# DPHY_TX0 register map
Vendor: Texas Instruments
Peripheral module from a debugger description file (folder J7_AHP).
Registers are 32-bit, read-write, reset 0x0 unless marked. A register's access mark holds for its fields unless they carry their own. Offsets are as the file gives them; lines under a group give offsets from that group; [hi:lo] are bit positions; {n}, {i} and the like mark numbered series; 'fields as' and 'values as' point back to an identical list; <NAME> marks a mode.

## DPHY_TX0 (part 1 of 2)
{0x0+4i} WIZ16B8M4CDT_CMN0_CMN_ANA_TBIT{i} (i=0..2)
  [31:0] CMN0_ANA_TBIT{i} — Analog Test register {i}
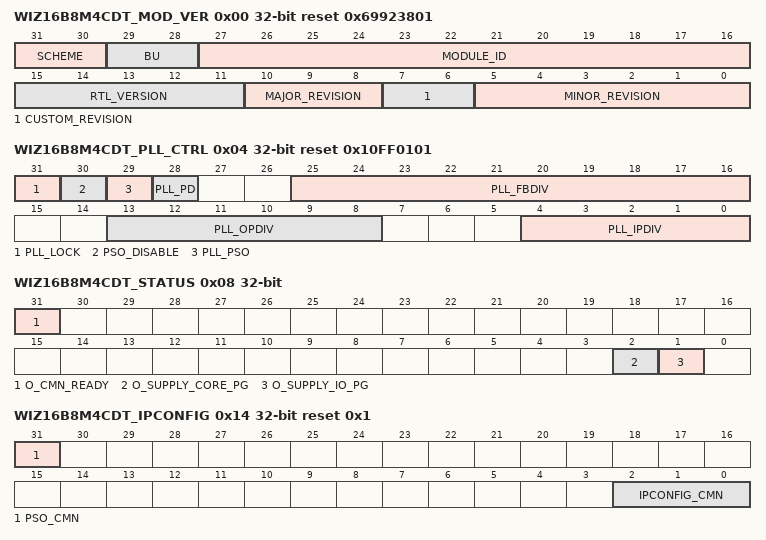
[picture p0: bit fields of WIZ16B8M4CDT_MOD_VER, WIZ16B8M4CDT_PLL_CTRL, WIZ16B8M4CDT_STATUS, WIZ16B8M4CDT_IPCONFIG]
0x00 WIZ16B8M4CDT_MOD_VER ro reset 0x69923801
  [31:30] SCHEME — Module Scheme
  [29:28] BU — Module Business Unit
  [27:16] MODULE_ID — WIZ16B8M4CDT module ID.
  [15:11] RTL_VERSION
  [10:8] MAJOR_REVISION
  [7:6] CUSTOM_REVISION
  [5:0] MINOR_REVISION
0x04 WIZ16B8M4CDT_PLL_CTRL access per field reset 0x10FF0101
  [31] PLL_LOCK ro — Signal to indicate that PLL has got locked. 1: PLL locked to required frequency 0: PLL not yet locked
  [30] PSO_DISABLE rw — Disables the ability to switch off the analog switched power islands in the lane when in the ultra-low power state
  [29] PLL_PSO rw — Power Shut Off signal for PLL 1: PLL shutoff 0: PLL power ON
  [28] PLL_PD rw — Power down signal for PLL (Does not switch off the PLL supply) 1: PLL is powered down 0: PLL is active
  [25:16] PLL_FBDIV rw — DPHY TX PLL VCO Feedback Divider ratio. Feedback divider value = ROUND ((Data Rate * 2 * pll_opdiv * pll_ipdiv) / PLL reference clock frequency)
  [13:8] PLL_OPDIV rw — DPHY TX PLL OUTCLK Divider ratio.<BR> 6'h01: Div by 1, 2.5 Gbps - 1.25 Gbps<BR> 6'h02: Div by 2, 1.24 Gbps - 630 Mbps<BR> 6'h04: Div by 4, 620 Mbps - 320 Mbps<BR> 6'h08: Div by 8, 310 Mbps - 160 Mbps<BR> 6'h10: Div by 16, 150 Mbps - 80 Mbps
  [4:0] PLL_IPDIV rw — DPHY TX PLL REFCLK Input Divider ratio.<BR> 5'h01: Div by 1, 9.6 MHz - <19.2 MHz<BR> 5'h02: Div by 2, 19.2 MHz - <38.4 MHz<BR> 5'h04: Div by 4, 38.4 MHz - < 76.8 MHz<BR> 5'h08: Div by 8, 76.8 MHz - < 150 MHz
0x08 WIZ16B8M4CDT_STATUS ro
  [31] O_CMN_READY — System Should check this during Power up Initialisation
  [2] O_SUPPLY_CORE_PG — The indicates the core supply is good.
  [1] O_SUPPLY_IO_PG — The indicates the IO supply is good.
0x0C WIZ16B8M4CDT_CMN0_CMN_ANA_TBIT3 access not given reset not defined
0x0C WIZ16B8M4CDT_RST_CTRL
  [31] LANE_RSTB_CMN — DPHY System Reset for Common Module - required to be released after APB register programming; See DPHY PMA specification for details of DPHY power up sequence
0x10 WIZ16B8M4CDT_CMN0_CMN_ANA_TBIT4
  [31:0] CMN0_ANA_TBIT4 — Analog Test register 4
0x10 WIZ16B8M4CDT_PSM_FREQ reset 0x1
  [7:0] PSM_CLOCK_FREQ — Static value based on System PSM clock frequency. The signal must be driven with a value such that the internal psm frequency of the divided psm clock is 1 MHz
0x14 WIZ16B8M4CDT_CMN0_CMN_ANA_TBIT5
  [7:0] CMN0_ANA_TBIT5 — Analog Test register 5
0x14 WIZ16B8M4CDT_IPCONFIG reset 0x1
  [31] PSO_CMN — Power Shutoff signal for CMN 1: CMN is power OFF 0: CMN is power ON
  [2:0] IPCONFIG_CMN — This signal decides which clock lane acts as master clock lane to all data lanes. Needed only for RXIP. Bit[2]: Reserved CASE {Bit[1],Bit[0]}: 00: Left RX clk lane provides clock to all left and right data lanes. 01: Left RX clk lane provides clock to all right data lanes, Right RX clk lane provides clock to all left data lanes. 10: Right RX clk lane provides clock to all right data lanes, Left RX clk lane provides clock to all left data lanes. 11: Right RX clk lane provides clock to all left and right data lanes.
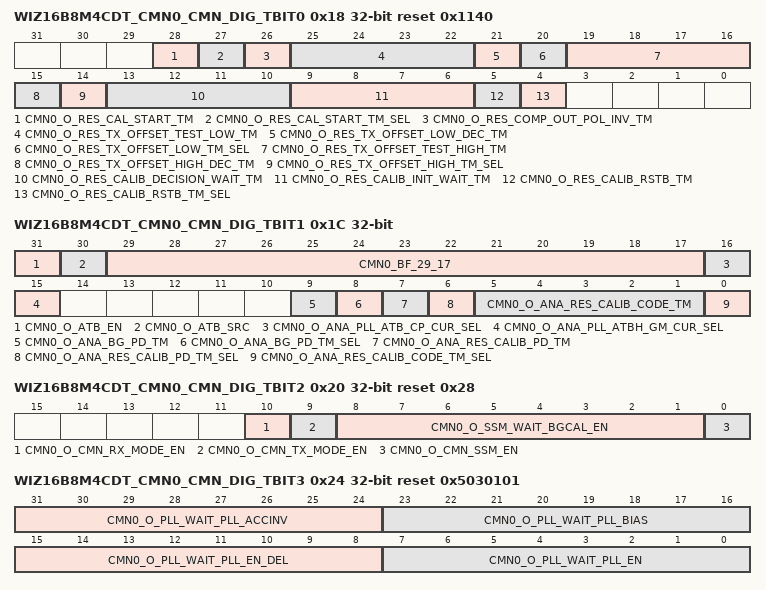
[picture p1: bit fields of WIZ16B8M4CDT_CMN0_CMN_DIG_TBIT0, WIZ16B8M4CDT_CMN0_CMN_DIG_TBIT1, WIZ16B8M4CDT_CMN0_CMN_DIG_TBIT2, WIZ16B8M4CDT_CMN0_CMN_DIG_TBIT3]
0x18 WIZ16B8M4CDT_CMN0_CMN_DIG_TBIT0 reset 0x1140
  [28] CMN0_O_RES_CAL_START_TM — res_cal_start in test mode
  [27] CMN0_O_RES_CAL_START_TM_SEL — res_cal_start select from test_mode
  [26] CMN0_O_RES_COMP_OUT_POL_INV_TM — Invert polarity for resistor calib comparator output
  [25:22] CMN0_O_RES_TX_OFFSET_TEST_LOW_TM — o_res_tx_offset_test_low_TM - Res calib manipulation code for res calib code low
  [21] CMN0_O_RES_TX_OFFSET_LOW_DEC_TM — o_res_tx_offset_low_dec_TM asserted - Perform increment manipulation on res calib code if o_res_tx_offset_low_TM_sel is asserted
  [20] CMN0_O_RES_TX_OFFSET_LOW_TM_SEL — o_res_tx_offset_low_TM_sel asserted - Enable offset manipulation for res calib code low
  [19:16] CMN0_O_RES_TX_OFFSET_TEST_HIGH_TM — o_res_tx_offset_test_high_TM - Res calib manipulation code for res calib code high
  [15] CMN0_O_RES_TX_OFFSET_HIGH_DEC_TM — o_res_tx_offset_high_dec_TM asserted - Perform increment manipulation on res calib code if o_res_tx_offset_high_TM_sel is asserted
  [14] CMN0_O_RES_TX_OFFSET_HIGH_TM_SEL — o_res_tx_offset_high_TM_sel asserted - Enable offset manipulation for res calib code high
  [13:10] CMN0_O_RES_CALIB_DECISION_WAIT_TM — res_calib decision wait time
  [9:6] CMN0_O_RES_CALIB_INIT_WAIT_TM — res_calib initial wait time
  [5] CMN0_O_RES_CALIB_RSTB_TM — w_res_calib_rstb value in testmode
  [4] CMN0_O_RES_CALIB_RSTB_TM_SEL — w_res_calib_rstb select from test_mode
0x1C WIZ16B8M4CDT_CMN0_CMN_DIG_TBIT1
  [31] CMN0_O_ATB_EN — ATB probing enabled
  [30] CMN0_O_ATB_SRC — Select IO for atb probing
  [29:17] CMN0_BF_29_17 — atb sel
  [16] CMN0_O_ANA_PLL_ATB_CP_CUR_SEL — o_ana_pll_atb_cp_cur_sel
  [15] CMN0_O_ANA_PLL_ATBH_GM_CUR_SEL — o_ana_pll_atbh_gm_cur_sel
  [9] CMN0_O_ANA_BG_PD_TM — o_ana_bg_pd value in testmode
  [8] CMN0_O_ANA_BG_PD_TM_SEL — o_ana_bg_pd select from test_mode
  [7] CMN0_O_ANA_RES_CALIB_PD_TM — o_ana_res_calib_pd value in testmode
  [6] CMN0_O_ANA_RES_CALIB_PD_TM_SEL — o_ana_res_calib_pd select from test_mode
  [5:1] CMN0_O_ANA_RES_CALIB_CODE_TM — o_ana_res_calib_code value in test_mode
  [0] CMN0_O_ANA_RES_CALIB_CODE_TM_SEL — o_ana_res_calib_code select from test_mode
0x20 WIZ16B8M4CDT_CMN0_CMN_DIG_TBIT2 reset 0x28
  [10] CMN0_O_CMN_RX_MODE_EN — Enable CMN RX related StateMachines
  [9] CMN0_O_CMN_TX_MODE_EN — Enable CMN TX related StateMachines
  [8:1] CMN0_O_SSM_WAIT_BGCAL_EN — Wait time for Calibrations enable after bandgap is enabled (in us)
  [0] CMN0_O_CMN_SSM_EN — Enable CMN startup state machine
0x24 WIZ16B8M4CDT_CMN0_CMN_DIG_TBIT3 reset 0x5030101
  [31:24] CMN0_O_PLL_WAIT_PLL_ACCINV — Wait time in pll_accinv (in us)
  [23:16] CMN0_O_PLL_WAIT_PLL_BIAS — Wait time in pll_bias (in us)
  [15:8] CMN0_O_PLL_WAIT_PLL_EN_DEL — Wait time in pll_en_del (in us)
  [7:0] CMN0_O_PLL_WAIT_PLL_EN — Wait time in PLL en (in us)
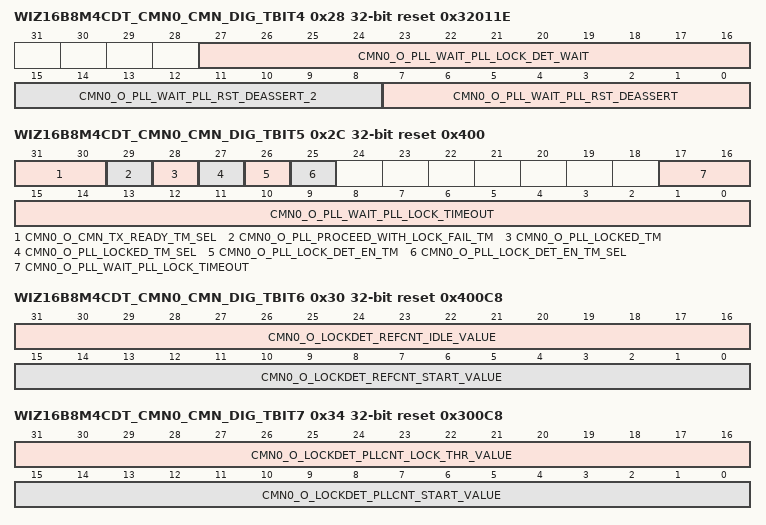
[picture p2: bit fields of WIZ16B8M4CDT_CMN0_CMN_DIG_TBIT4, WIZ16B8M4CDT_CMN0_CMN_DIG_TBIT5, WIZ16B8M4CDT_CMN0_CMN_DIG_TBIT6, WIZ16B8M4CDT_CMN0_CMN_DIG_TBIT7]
0x28 WIZ16B8M4CDT_CMN0_CMN_DIG_TBIT4 reset 0x32011E
  [27:16] CMN0_O_PLL_WAIT_PLL_LOCK_DET_WAIT — Wait time in pll_lock_det_wait (in us)
  [15:8] CMN0_O_PLL_WAIT_PLL_RST_DEASSERT_2 — Wait time in pll_rst_deassert_2ndset (in us)
  [7:0] CMN0_O_PLL_WAIT_PLL_RST_DEASSERT — Wait time in pll_rst_deassert (in us)
0x2C WIZ16B8M4CDT_CMN0_CMN_DIG_TBIT5 reset 0x400
  [31:30] CMN0_O_CMN_TX_READY_TM_SEL — ATB probing enabled
  [29] CMN0_O_PLL_PROCEED_WITH_LOCK_FAIL_TM — o_ana_pll_atb_cp_cur_sel
  [28] CMN0_O_PLL_LOCKED_TM — Forced value of pll_locked going to fsm = 1
  [27] CMN0_O_PLL_LOCKED_TM_SEL — pll_locked going to fsm forced from test registers
  [26] CMN0_O_PLL_LOCK_DET_EN_TM — Forced value of pll_lock_det_en = 1
  [25] CMN0_O_PLL_LOCK_DET_EN_TM_SEL — pll_lock_det_en forced from test registers
  [17:0] CMN0_O_PLL_WAIT_PLL_LOCK_TIMEOUT — Wait time for pll_lock_timeout (in us)
0x30 WIZ16B8M4CDT_CMN0_CMN_DIG_TBIT6 reset 0x400C8
  [31:16] CMN0_O_LOCKDET_REFCNT_IDLE_VALUE — refcnt idle value for PLL lock detect module
  [15:0] CMN0_O_LOCKDET_REFCNT_START_VALUE — refcnt start value for PLL lock detect module
0x34 WIZ16B8M4CDT_CMN0_CMN_DIG_TBIT7 reset 0x300C8
  [31:16] CMN0_O_LOCKDET_PLLCNT_LOCK_THR_VALUE — pllcnt lock threshold value for PLL lock detect module
  [15:0] CMN0_O_LOCKDET_PLLCNT_START_VALUE — pllcnt start value for PLL lock detect module
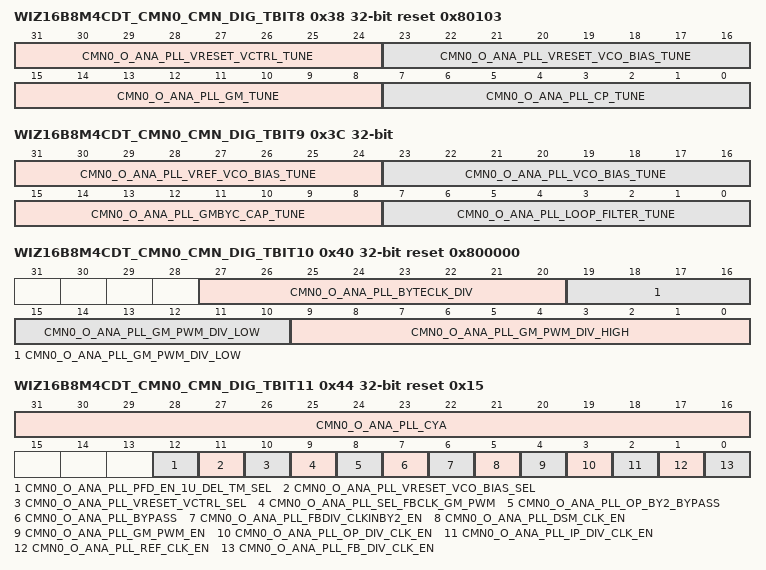
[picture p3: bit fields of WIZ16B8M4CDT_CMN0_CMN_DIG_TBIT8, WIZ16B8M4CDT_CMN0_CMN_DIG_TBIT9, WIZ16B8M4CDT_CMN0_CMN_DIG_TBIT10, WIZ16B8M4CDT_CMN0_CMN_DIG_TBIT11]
0x38 WIZ16B8M4CDT_CMN0_CMN_DIG_TBIT8 reset 0x80103
  [31:24] CMN0_O_ANA_PLL_VRESET_VCTRL_TUNE — unconnected, intended for vreset_vctrl(CP output) progrmmability
  [23:16] CMN0_O_ANA_PLL_VRESET_VCO_BIAS_TUNE — Programmability for vco bias(gmbyc) initial voltage
  [15:8] CMN0_O_ANA_PLL_GM_TUNE — gm tune value for PLL
  [7:0] CMN0_O_ANA_PLL_CP_TUNE — Charge Pump Tune value for PLL
0x3C WIZ16B8M4CDT_CMN0_CMN_DIG_TBIT9
  [31:24] CMN0_O_ANA_PLL_VREF_VCO_BIAS_TUNE — Tuning Control for reference vco bias in PLL
  [23:16] CMN0_O_ANA_PLL_VCO_BIAS_TUNE — Tuning Control for PLL vco bias
  [15:8] CMN0_O_ANA_PLL_GMBYC_CAP_TUNE — gmbyc tune value for PLL
  [7:0] CMN0_O_ANA_PLL_LOOP_FILTER_TUNE — Tuning Control for loop filter
0x40 WIZ16B8M4CDT_CMN0_CMN_DIG_TBIT10 reset 0x800000
  [27:20] CMN0_O_ANA_PLL_BYTECLK_DIV — Byteclk divider value
  [19:10] CMN0_O_ANA_PLL_GM_PWM_DIV_LOW — Low division value setting for the gm PWM control divider
  [9:0] CMN0_O_ANA_PLL_GM_PWM_DIV_HIGH — High division value setting for the gm PWM control divider
0x44 WIZ16B8M4CDT_CMN0_CMN_DIG_TBIT11 reset 0x15
  [31:16] CMN0_O_ANA_PLL_CYA — Drives pllda_cya going to ANA
  [12] CMN0_O_ANA_PLL_PFD_EN_1U_DEL_TM_SEL — Testmode signal for selecting 1us delayed for pll_pfd_reset_n
  [11] CMN0_O_ANA_PLL_VRESET_VCO_BIAS_SEL — vreset_vctrl_gmbyc is set inside the pll_vreset_gen
  [10] CMN0_O_ANA_PLL_VRESET_VCTRL_SEL — vreset_vctrl is set to ground inside the pll_vreset_gen
  [9] CMN0_O_ANA_PLL_SEL_FBCLK_GM_PWM — Enable mode to use feedback clock as the PWM control input for the gm stage
  [8] CMN0_O_ANA_PLL_OP_BY2_BYPASS — Mode to bypass the divide by 2 in the PLL output which generates clk_bit and clk_bitb
  [7] CMN0_O_ANA_PLL_BYPASS — Bypass PLL and pass refclk as output
  [6] CMN0_O_ANA_PLL_FBDIV_CLKINBY2_EN — Enable division by 2 on the feedback divider input clock
  [5] CMN0_O_ANA_PLL_DSM_CLK_EN — Enable for dsm clock output to digital
  [4] CMN0_O_ANA_PLL_GM_PWM_EN — Enable PWM control of the gm, else it will operate in the continuous mode
  [3] CMN0_O_ANA_PLL_OP_DIV_CLK_EN — Enable for op divider clock output to digital
  [2] CMN0_O_ANA_PLL_IP_DIV_CLK_EN — Enable for ip divider output to digital
  [1] CMN0_O_ANA_PLL_REF_CLK_EN — enables refclk to PLL
  [0] CMN0_O_ANA_PLL_FB_DIV_CLK_EN — Enable for feedback clock output to digital
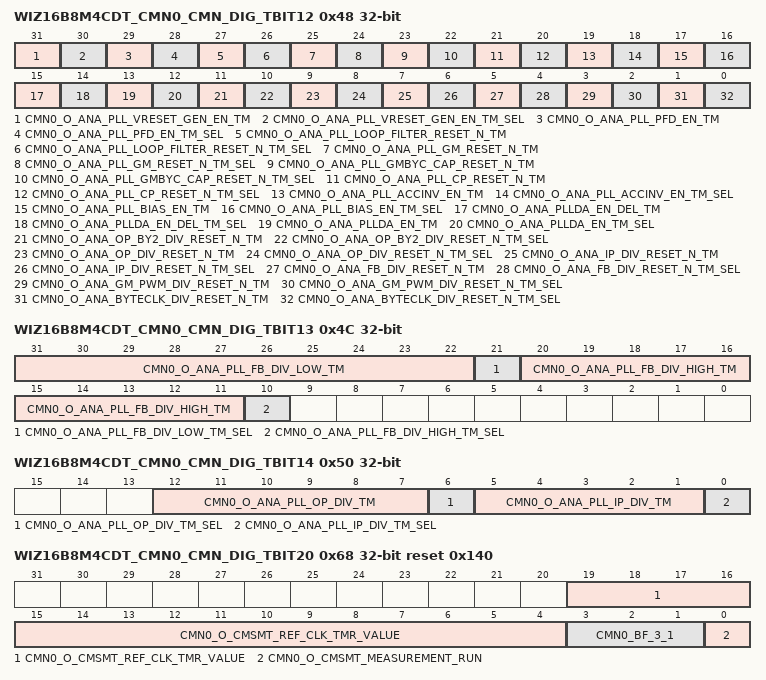
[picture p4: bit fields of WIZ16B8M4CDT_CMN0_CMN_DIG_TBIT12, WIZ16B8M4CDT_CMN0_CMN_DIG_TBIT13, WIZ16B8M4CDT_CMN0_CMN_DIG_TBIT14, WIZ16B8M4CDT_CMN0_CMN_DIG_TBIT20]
0x48 WIZ16B8M4CDT_CMN0_CMN_DIG_TBIT12
  [31] CMN0_O_ANA_PLL_VRESET_GEN_EN_TM — Forced value of pll_vreset_gen_en = 1
  [30] CMN0_O_ANA_PLL_VRESET_GEN_EN_TM_SEL — pll_vreset_gen_en forced from test registers
  [29] CMN0_O_ANA_PLL_PFD_EN_TM — Forced value of pllda_pfd_en = 1
  [28] CMN0_O_ANA_PLL_PFD_EN_TM_SEL — pllda_pfd_en forced from test registers
  [27] CMN0_O_ANA_PLL_LOOP_FILTER_RESET_N_TM — Forced value of pll_loop_filter_reset_n = 1
  [26] CMN0_O_ANA_PLL_LOOP_FILTER_RESET_N_TM_SEL — pll_loop_filter_reset_n is drivne from test registers
  [25] CMN0_O_ANA_PLL_GM_RESET_N_TM — Forced value of pll_gm_reset_n = 1
  [24] CMN0_O_ANA_PLL_GM_RESET_N_TM_SEL — pll_gm_reset_n is drivne from test registers
  [23] CMN0_O_ANA_PLL_GMBYC_CAP_RESET_N_TM — Forced value of pll_gmbyc_cap_reset_n = 1
  [22] CMN0_O_ANA_PLL_GMBYC_CAP_RESET_N_TM_SEL — pll_gmbyc_cap_reset_n is drivne from test registers
  [21] CMN0_O_ANA_PLL_CP_RESET_N_TM — Forced value of pll_cp_reset_n = 1
  [20] CMN0_O_ANA_PLL_CP_RESET_N_TM_SEL — pll_cp_reset_n is drivne from test registers
  [19] CMN0_O_ANA_PLL_ACCINV_EN_TM — Forced value of pllda_accinv = 1
  [18] CMN0_O_ANA_PLL_ACCINV_EN_TM_SEL — pllda_accinv forced from test registers
  [17] CMN0_O_ANA_PLL_BIAS_EN_TM — Forced value of pllda_bias_en = 1
  [16] CMN0_O_ANA_PLL_BIAS_EN_TM_SEL — pllda_bias_en forced from test registers
  [15] CMN0_O_ANA_PLLDA_EN_DEL_TM — Forced value of pllda_en_del = 1
  [14] CMN0_O_ANA_PLLDA_EN_DEL_TM_SEL — pllda_en_del forced from test registers
  [13] CMN0_O_ANA_PLLDA_EN_TM — Forced value of pllda_en_del = 1
  [12] CMN0_O_ANA_PLLDA_EN_TM_SEL — pllda_en_del forced from test registers
  [11] CMN0_O_ANA_OP_BY2_DIV_RESET_N_TM — Forced valu of pllda_op_by2_div_reset_n = 1
  [10] CMN0_O_ANA_OP_BY2_DIV_RESET_N_TM_SEL — pllda_op_by2_div_reset_n forced from test registers
  [9] CMN0_O_ANA_OP_DIV_RESET_N_TM — Forced value of pllda_op_div_reset_n = 1
  [8] CMN0_O_ANA_OP_DIV_RESET_N_TM_SEL — pllda_op_div_reset_n forced from test registers
  [7] CMN0_O_ANA_IP_DIV_RESET_N_TM — Forced value of pllda_ip_div_reset_n = 1
  [6] CMN0_O_ANA_IP_DIV_RESET_N_TM_SEL — pllda_ip_div_reset_n forced from test registers
  [5] CMN0_O_ANA_FB_DIV_RESET_N_TM — Forced value of pllda_fb_div_reset_n = 1
  [4] CMN0_O_ANA_FB_DIV_RESET_N_TM_SEL — pllda_fb_div_reset_n forced from test registers
  [3] CMN0_O_ANA_GM_PWM_DIV_RESET_N_TM — Forced value of pllda_gm_pwm_div_reset_n = 1
  [2] CMN0_O_ANA_GM_PWM_DIV_RESET_N_TM_SEL — pllda_gm_pwm_div_reset_n forced from test registers
  [1] CMN0_O_ANA_BYTECLK_DIV_RESET_N_TM — Forced value of pllda_byteclk_div_reset_n = 1
  [0] CMN0_O_ANA_BYTECLK_DIV_RESET_N_TM_SEL — pllda_byteclk_div_reset_n forced from test registers
0x4C WIZ16B8M4CDT_CMN0_CMN_DIG_TBIT13
  [31:22] CMN0_O_ANA_PLL_FB_DIV_LOW_TM — forced value for pll_fb_div_clk_low
  [21] CMN0_O_ANA_PLL_FB_DIV_LOW_TM_SEL — pll_fb_div_clk_low forced from test registers
  [20:11] CMN0_O_ANA_PLL_FB_DIV_HIGH_TM — forced value for pll_fb_div_clk_high
  [10] CMN0_O_ANA_PLL_FB_DIV_HIGH_TM_SEL — pll_fb_div_clk_high forced from test registers
0x50 WIZ16B8M4CDT_CMN0_CMN_DIG_TBIT14
  [12:7] CMN0_O_ANA_PLL_OP_DIV_TM — forced value for op_div
  [6] CMN0_O_ANA_PLL_OP_DIV_TM_SEL — op_div forced from test registers
  [5:1] CMN0_O_ANA_PLL_IP_DIV_TM — forced value for ip_div
  [0] CMN0_O_ANA_PLL_IP_DIV_TM_SEL — ip_div forced from test registers
0x68 WIZ16B8M4CDT_CMN0_CMN_DIG_TBIT20 reset 0x140
  [19:4] CMN0_O_CMSMT_REF_CLK_TMR_VALUE — Number of refclk cycles required for clock measurement
  [3:1] CMN0_BF_3_1 — test clock
  [0] CMN0_O_CMSMT_MEASUREMENT_RUN — Enables clock measurement
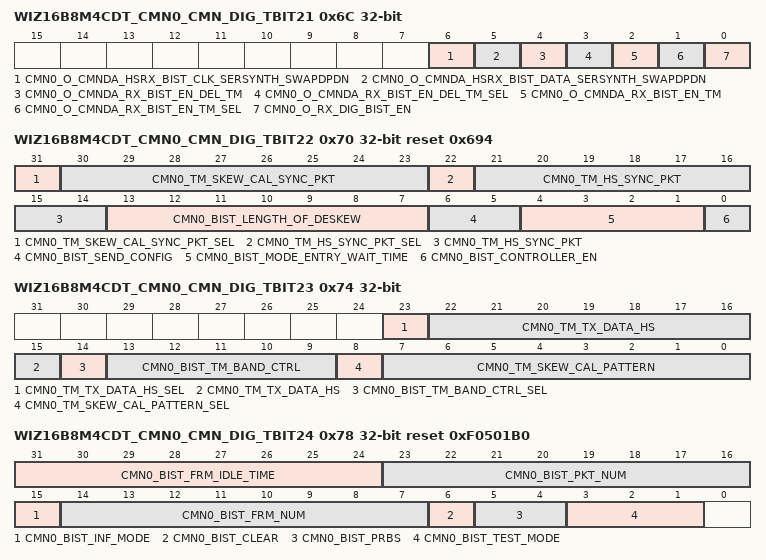
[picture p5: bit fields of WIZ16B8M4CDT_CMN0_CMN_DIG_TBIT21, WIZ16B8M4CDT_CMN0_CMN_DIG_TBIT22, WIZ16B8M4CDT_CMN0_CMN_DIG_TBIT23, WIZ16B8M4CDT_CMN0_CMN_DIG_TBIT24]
0x6C WIZ16B8M4CDT_CMN0_CMN_DIG_TBIT21
  [6] CMN0_O_CMNDA_HSRX_BIST_CLK_SERSYNTH_SWAPDPDN — Enables swapping DP-DN lines for clock bist
  [5] CMN0_O_CMNDA_HSRX_BIST_DATA_SERSYNTH_SWAPDPDN — Enables swapping DP-DN lines for data bist
  [4] CMN0_O_CMNDA_RX_BIST_EN_DEL_TM — forced value of cmnda_rx_bist_en_del = 1
  [3] CMN0_O_CMNDA_RX_BIST_EN_DEL_TM_SEL — cmnda_rx_bist_en_del driven from test registers
  [2] CMN0_O_CMNDA_RX_BIST_EN_TM — forced value of cmnda_rx_bist_en = 1
  [1] CMN0_O_CMNDA_RX_BIST_EN_TM_SEL — cmnda_rx_bist_en driven from test registers
  [0] CMN0_O_RX_DIG_BIST_EN — BIST enable for digital
0x70 WIZ16B8M4CDT_CMN0_CMN_DIG_TBIT22 reset 0x694
  [31] CMN0_TM_SKEW_CAL_SYNC_PKT_SEL — To send 'FF as Skew calibration sync packet
  [30:23] CMN0_TM_SKEW_CAL_SYNC_PKT — desired skew calibration test sync packet
  [22] CMN0_TM_HS_SYNC_PKT_SEL — To send 'B8 as HS sync packet
  [21:14] CMN0_TM_HS_SYNC_PKT — desired HS test sync packet
  [13:7] CMN0_BIST_LENGTH_OF_DESKEW — Length of deskew sequence In terms of us. By default 13us of deskew sequence will be transmitted
  [6:5] CMN0_BIST_SEND_CONFIG — Option of configuring what to send in BIST mose. To send both deskew and HS data
  [4:1] CMN0_BIST_MODE_ENTRY_WAIT_TIME — Once after giving bist_en signal to pattern generator, after these many number of BYTE clcok cycles pattern generation will start
  [0] CMN0_BIST_CONTROLLER_EN — Enable BIST controller
0x74 WIZ16B8M4CDT_CMN0_CMN_DIG_TBIT23
  [23] CMN0_TM_TX_DATA_HS_SEL — sends single test byte to sersynth, which is in <22:15>
  [22:15] CMN0_TM_TX_DATA_HS — Desired clock patetrn that can be sent using clk_sersynth
  [14] CMN0_BIST_TM_BAND_CTRL_SEL — To take the default band control settigns by the design
  [13:9] CMN0_BIST_TM_BAND_CTRL — Test mode band control setting to be done for BIST
  [8] CMN0_TM_SKEW_CAL_PATTERN_SEL — To send 'AA as skew calibration pattern
  [7:0] CMN0_TM_SKEW_CAL_PATTERN — desired skew calibration test sequence
0x78 WIZ16B8M4CDT_CMN0_CMN_DIG_TBIT24 reset 0xF0501B0
  [31:24] CMN0_BIST_FRM_IDLE_TIME — BIST_FRM_IDLE time is time between the frames
  [23:16] CMN0_BIST_PKT_NUM — BIST_PAK_NUM is number of packets that are to be transmitted per frame
  [15] CMN0_BIST_INF_MODE — run infinite BIST mode
  [14:7] CMN0_BIST_FRM_NUM — BIST_FRM_NUM is number of frames to be transmitted
  [6] CMN0_BIST_CLEAR — clear the bist
  [5:4] CMN0_BIST_PRBS — BIST PRBS MODE 9
  [3:1] CMN0_BIST_TEST_MODE — PRBS mode
0x7C WIZ16B8M4CDT_CMN0_CMN_DIG_TBIT25 reset 0x28
  [11:0] CMN0_BIST_RUN_LENGTH — BIST_RUN_LENGTH
0x80 WIZ16B8M4CDT_CMN0_CMN_DIG_TBIT26 reset 0xA
  [7:0] CMN0_BIST_IDLE_TIME — BIST_IDLE_TIME
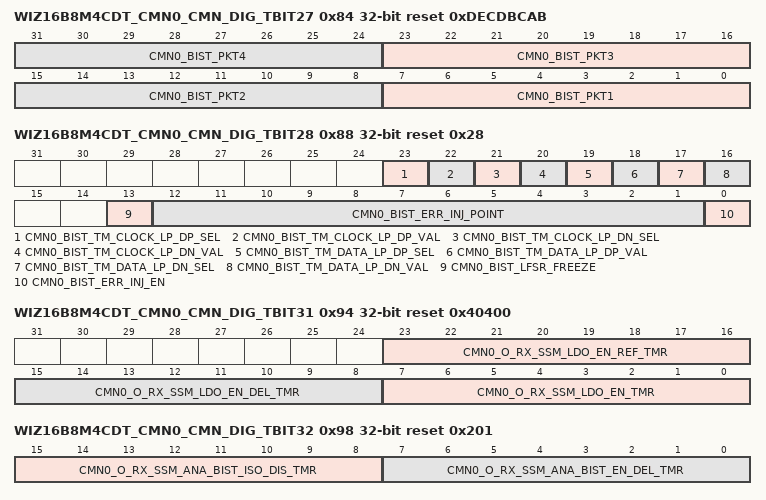
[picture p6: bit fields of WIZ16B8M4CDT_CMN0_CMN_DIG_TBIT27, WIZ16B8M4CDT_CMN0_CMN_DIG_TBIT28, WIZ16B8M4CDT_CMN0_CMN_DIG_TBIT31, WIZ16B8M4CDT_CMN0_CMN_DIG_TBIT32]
0x84 WIZ16B8M4CDT_CMN0_CMN_DIG_TBIT27 reset 0xDECDBCAB
  [8n-1:8n-8] CMN0_BIST_PKT{n} (n=1..4) — BIST_TEST_PAT{n}
0x88 WIZ16B8M4CDT_CMN0_CMN_DIG_TBIT28 reset 0x28
  [23] CMN0_BIST_TM_CLOCK_LP_DP_SEL — Test mode selection bit to force clcok LP DP buffer to value from design
  [22] CMN0_BIST_TM_CLOCK_LP_DP_VAL — Test mode clock LP DP buffer value is 0
  [21] CMN0_BIST_TM_CLOCK_LP_DN_SEL — Test mode selection bit to force clcok LP DN buffer to value from design
  [20] CMN0_BIST_TM_CLOCK_LP_DN_VAL — Test mode clock LP DN buffer value is 0
  [19] CMN0_BIST_TM_DATA_LP_DP_SEL — Test mode selection bit to force data LP DP buffer to value from design
  [18] CMN0_BIST_TM_DATA_LP_DP_VAL — Test mode data LP DP buffer value is 0
  [17] CMN0_BIST_TM_DATA_LP_DN_SEL — Test mode selection bit to force data LP DN buffer to value from design
  [16] CMN0_BIST_TM_DATA_LP_DN_VAL — Test mode data LP DN buffer value is 0
  [13] CMN0_BIST_LFSR_FREEZE — Reset LFSR contents after every packet or frame
  [12:1] CMN0_BIST_ERR_INJ_POINT — BIST_ERR_INJECT_POINT is where to inject the error in the packet
  [0] CMN0_BIST_ERR_INJ_EN — Inject error in the BIST during the packet
0x94 WIZ16B8M4CDT_CMN0_CMN_DIG_TBIT31 reset 0x40400
  [23:16] CMN0_O_RX_SSM_LDO_EN_REF_TMR — Wait time before enabling oscialltor calibration
  [15:8] CMN0_O_RX_SSM_LDO_EN_DEL_TMR — wait time before enabling ldo_en_ref
  [7:0] CMN0_O_RX_SSM_LDO_EN_TMR — Wait time between ldo_en and ldo_en_del
0x98 WIZ16B8M4CDT_CMN0_CMN_DIG_TBIT32 reset 0x201
  [15:8] CMN0_O_RX_SSM_ANA_BIST_ISO_DIS_TMR — Wait time between Bist_en_del and disabling isolation
  [7:0] CMN0_O_RX_SSM_ANA_BIST_EN_DEL_TMR — Wait time between Bist_en and bist_en_Del
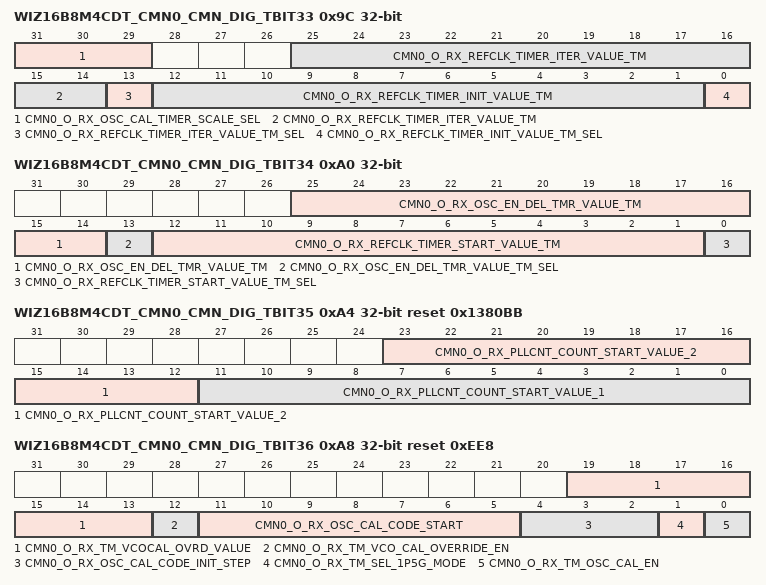
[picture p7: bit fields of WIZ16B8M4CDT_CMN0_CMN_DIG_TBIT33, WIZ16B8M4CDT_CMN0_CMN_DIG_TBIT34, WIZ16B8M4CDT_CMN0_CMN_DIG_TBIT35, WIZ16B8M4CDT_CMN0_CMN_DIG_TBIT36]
0x9C WIZ16B8M4CDT_CMN0_CMN_DIG_TBIT33
  [31:29] CMN0_O_RX_OSC_CAL_TIMER_SCALE_SEL — Timer scale value for vco_count_window
  [25:14] CMN0_O_RX_REFCLK_TIMER_ITER_VALUE_TM — Wait time required before enabling vco count window during iteration in test mode
  [13] CMN0_O_RX_REFCLK_TIMER_ITER_VALUE_TM_SEL — refclk_timer_iter value driven from test register
  [12:1] CMN0_O_RX_REFCLK_TIMER_INIT_VALUE_TM — Wait time required before enabling vco count window in initial phase in test mode
  [0] CMN0_O_RX_REFCLK_TIMER_INIT_VALUE_TM_SEL — refclk_timer_init value driven from test register
0xA0 WIZ16B8M4CDT_CMN0_CMN_DIG_TBIT34
  [25:14] CMN0_O_RX_OSC_EN_DEL_TMR_VALUE_TM — Wait time between osc_en and osc_en_del in Test mode
  [13] CMN0_O_RX_OSC_EN_DEL_TMR_VALUE_TM_SEL — osc_en_del_tmr driven from test register
  [12:1] CMN0_O_RX_REFCLK_TIMER_START_VALUE_TM — No of refclk cycles required for single vco count window in test mode
  [0] CMN0_O_RX_REFCLK_TIMER_START_VALUE_TM_SEL — refclk_timer_start_value driven from test mode
0xA4 WIZ16B8M4CDT_CMN0_CMN_DIG_TBIT35 reset 0x1380BB
  [23:12] CMN0_O_RX_PLLCNT_COUNT_START_VALUE_2 — No of PLL clock cycles expected in 2.5G mode
  [11:0] CMN0_O_RX_PLLCNT_COUNT_START_VALUE_1 — No of PLL clock cycles expected in 1.5G mode
0xA8 WIZ16B8M4CDT_CMN0_CMN_DIG_TBIT36 reset 0xEE8
  [19:13] CMN0_O_RX_TM_VCOCAL_OVRD_VALUE — Vco calcode Test mode value
  [12] CMN0_O_RX_TM_VCO_CAL_OVERRIDE_EN — Enables test mode overwrite for vco cal code
  [11:5] CMN0_O_RX_OSC_CAL_CODE_START — Starting code for vco calibration
  [4:2] CMN0_O_RX_OSC_CAL_CODE_INIT_STEP — Step size for incrmenting vco cal code
  [1] CMN0_O_RX_TM_SEL_1P5G_MODE — Select 1p5g mode oscillator clock
  [0] CMN0_O_RX_TM_OSC_CAL_EN — Test mode overwrite for crude osc calibration enable
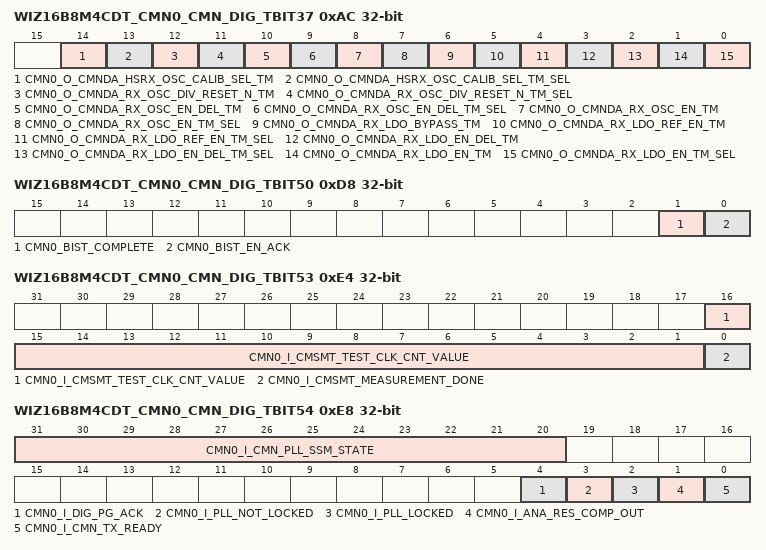
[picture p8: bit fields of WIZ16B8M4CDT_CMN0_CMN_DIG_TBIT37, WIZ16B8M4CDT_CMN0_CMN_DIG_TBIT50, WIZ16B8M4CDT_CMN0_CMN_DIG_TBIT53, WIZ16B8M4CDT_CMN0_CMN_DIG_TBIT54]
0xAC WIZ16B8M4CDT_CMN0_CMN_DIG_TBIT37
  [14] CMN0_O_CMNDA_HSRX_OSC_CALIB_SEL_TM — forced value of hsrx_osc_calib_sel = 1
  [13] CMN0_O_CMNDA_HSRX_OSC_CALIB_SEL_TM_SEL — hsrx_osc_calib_sel driven from test registers
  [12] CMN0_O_CMNDA_RX_OSC_DIV_RESET_N_TM — forced value of rx_osc_div_reset_n = 1
  [11] CMN0_O_CMNDA_RX_OSC_DIV_RESET_N_TM_SEL — rx_osc_div_reset_n driven from test registers
  [10] CMN0_O_CMNDA_RX_OSC_EN_DEL_TM — forced value of rx_osc_en_del = 1
  [9] CMN0_O_CMNDA_RX_OSC_EN_DEL_TM_SEL — rx_osc_en_del driven from test registers
  [8] CMN0_O_CMNDA_RX_OSC_EN_TM — forced value of rx_osc_en = 1
  [7] CMN0_O_CMNDA_RX_OSC_EN_TM_SEL — rx_osc_en driven from test registers
  [6] CMN0_O_CMNDA_RX_LDO_BYPASS_TM — Bypass LDO in test mode
  [5] CMN0_O_CMNDA_RX_LDO_REF_EN_TM — forced value of rx_ldo_ref_en = 1
  [4] CMN0_O_CMNDA_RX_LDO_REF_EN_TM_SEL — rx_ldo_ref_en driven from test registers
  [3] CMN0_O_CMNDA_RX_LDO_EN_DEL_TM — forced value of rx_ldo_en_del = 1
  [2] CMN0_O_CMNDA_RX_LDO_EN_DEL_TM_SEL — rx_ldo_en_del driven from test registers
  [1] CMN0_O_CMNDA_RX_LDO_EN_TM — forced value of rx_ldo_en = 1
  [0] CMN0_O_CMNDA_RX_LDO_EN_TM_SEL — rx_ldo_en driven from test registers
0xB4 WIZ16B8M4CDT_CMN0_CMN_DIG_TBIT39
  [31:0] CMN0_SPARE — spare
0xD8 WIZ16B8M4CDT_CMN0_CMN_DIG_TBIT50 ro
  [1] CMN0_BIST_COMPLETE — BIST is completed
  [0] CMN0_BIST_EN_ACK — BIST Controller is enabled
0xE4 WIZ16B8M4CDT_CMN0_CMN_DIG_TBIT53 ro
  [16:1] CMN0_I_CMSMT_TEST_CLK_CNT_VALUE — Gives clocks cycles count for test clock during measurement
  [0] CMN0_I_CMSMT_MEASUREMENT_DONE — Indicates clock measurement is done
0xE8 WIZ16B8M4CDT_CMN0_CMN_DIG_TBIT54 ro
  [31:20] CMN0_I_CMN_PLL_SSM_STATE — Gives CMN PLL ssm state
  [4] CMN0_I_DIG_PG_ACK — PSM power good acknowledgement
  [3] CMN0_I_PLL_NOT_LOCKED — Indicates PLL is not locked before timeout
  [2] CMN0_I_PLL_LOCKED — Indicates PLL is locked
  [1] CMN0_I_ANA_RES_COMP_OUT — read value of comaprator output
  [0] CMN0_I_CMN_TX_READY — Indiacates cmn is ready for TX IP
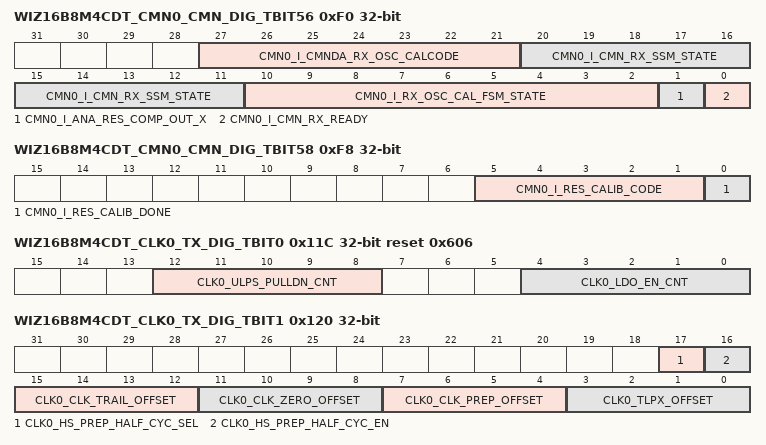
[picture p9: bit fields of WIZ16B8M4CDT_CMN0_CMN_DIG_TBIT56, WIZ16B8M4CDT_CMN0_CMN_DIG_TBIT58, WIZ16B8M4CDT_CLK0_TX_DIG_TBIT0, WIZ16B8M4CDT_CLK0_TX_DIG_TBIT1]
0xF0 WIZ16B8M4CDT_CMN0_CMN_DIG_TBIT56 ro
  [27:21] CMN0_I_CMNDA_RX_OSC_CALCODE — Reads out calib code applied to osicllator
  [20:11] CMN0_I_CMN_RX_SSM_STATE — Gives CMN Rx ssm state
  [10:2] CMN0_I_RX_OSC_CAL_FSM_STATE — Gives Rx osc calib FSM state
  [1] CMN0_I_ANA_RES_COMP_OUT_X — read value of comaprator output
  [0] CMN0_I_CMN_RX_READY — Indicates cmn is ready for RX IP
0xF8 WIZ16B8M4CDT_CMN0_CMN_DIG_TBIT58 ro
  [5:1] CMN0_I_RES_CALIB_CODE — Gives out calibrated resistor calibration code
  [0] CMN0_I_RES_CALIB_DONE — Indicates resistor calibration is done
0xF8 WIZ16B8M4CDT_PLLRES
  [7:0] PLLREFSEL_CMN — PLL frequency range. This signal is not being used currently. Should be 8'd0
0xFC WIZ16B8M4CDT_DIAG_TEST
  [31:0] DIAG_REG — Diagnostic register.
{0x100+4i} WIZ16B8M4CDT_CLK0_TX_ANA_TBIT{i} (i=0..4)
  [31:0] CLK0_ANA_TBIT{i} — Analog Test register {i}
0x11C WIZ16B8M4CDT_CLK0_TX_DIG_TBIT0 reset 0x606
  [12:8] CLK0_ULPS_PULLDN_CNT — After enabling LDO, ulps_pulldn will go to 0 after these many uS
  [4:0] CLK0_LDO_EN_CNT — Once the analog's power down signal is de asserted, LDO will be enabled after these many uS
0x120 WIZ16B8M4CDT_CLK0_TX_DIG_TBIT1
  [17] CLK0_HS_PREP_HALF_CYC_SEL — HS Prepare extra half cycle offset is controlled by digital logic
  [16] CLK0_HS_PREP_HALF_CYC_EN — If bit 17 == 1, Sets HS Prepare extra offset to 0 half cycle
  [15:12] CLK0_CLK_TRAIL_OFFSET — Sets CLK-TRAIL Offset to 0
  [11:8] CLK0_CLK_ZERO_OFFSET — Sets CLK-ZERO offset to 0
  [7:4] CLK0_CLK_PREP_OFFSET — Sets CLK-PREPARE offset to 0
  [3:0] CLK0_TLPX_OFFSET — Sets TLPX Offset to 0
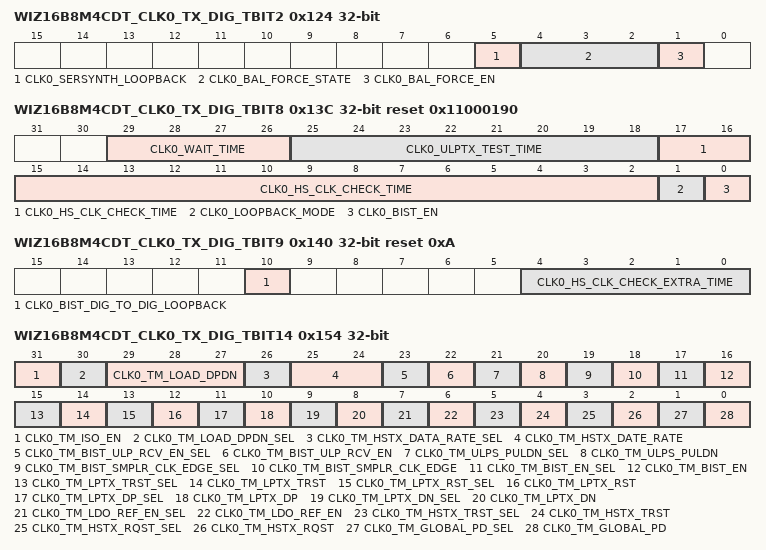
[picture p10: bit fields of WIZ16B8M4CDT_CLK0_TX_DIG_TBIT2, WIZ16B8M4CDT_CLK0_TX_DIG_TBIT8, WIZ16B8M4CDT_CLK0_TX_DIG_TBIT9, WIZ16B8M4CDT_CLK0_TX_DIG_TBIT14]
0x124 WIZ16B8M4CDT_CLK0_TX_DIG_TBIT2
  [5] CLK0_SERSYNTH_LOOPBACK — De-serialiser will take input from sampler
  [4:2] CLK0_BAL_FORCE_STATE — Force the SYNC packet detection logic into below states if <1> is '1', SYNC_DONE state
  [1] CLK0_BAL_FORCE_EN — SYNC packet detection FSM in serialiser in BIST mode will work as per logic
0x13C WIZ16B8M4CDT_CLK0_TX_DIG_TBIT8 reset 0x11000190
  [29:26] CLK0_WAIT_TIME — Wait time between posedge run and negedge run of sampler clock
  [25:18] CLK0_ULPTX_TEST_TIME — While testing ULPTX, LP00 will be maintained on DPDN for this many number of byte clock cycles
  [17:2] CLK0_HS_CLK_CHECK_TIME — For how much time clock pattern will be checked for transitions. This value will be counted on byte clock
  [1] CLK0_LOOPBACK_MODE — Internal Loopback mode
  [0] CLK0_BIST_EN — BIST Disabled
0x140 WIZ16B8M4CDT_CLK0_TX_DIG_TBIT9 reset 0xA
  [10] CLK0_BIST_DIG_TO_DIG_LOOPBACK — main digital to pattern checker loopback enabled
  [4:0] CLK0_HS_CLK_CHECK_EXTRA_TIME — After the clock has been transmitted for programmed number of byte clock cycles, if we need clock to be sent for some more time, set this value as per requiremnt
0x144 WIZ16B8M4CDT_CLK0_TX_DIG_TBIT10
  [31:0] CLK0_SPARE — spare
0x154 WIZ16B8M4CDT_CLK0_TX_DIG_TBIT14
  [31] CLK0_TM_ISO_EN — Enable isolation in test mode
  [30] CLK0_TM_LOAD_DPDN_SEL — Take ana_dpdn_load from dig logic
  [29:27] CLK0_TM_LOAD_DPDN — set ana_dpdn_load as per requirement in test mode
  [26] CLK0_TM_HSTX_DATA_RATE_SEL — Take ana_hstx_datarate from dig logic
  [25:24] CLK0_TM_HSTX_DATE_RATE — set ana_hstx_datarate as per requirement in test mode
  [23] CLK0_TM_BIST_ULP_RCV_EN_SEL — Take ana_bist_ulps_rcv_en from dig logic
  [22] CLK0_TM_BIST_ULP_RCV_EN — set ana_bist_ulps_rcv_en to 0
  [21] CLK0_TM_ULPS_PULDN_SEL — Take ana_ulps_puldn from dig logic
  [20] CLK0_TM_ULPS_PULDN — set ana_ulps_puldn to 0
  [19] CLK0_TM_BIST_SMPLR_CLK_EDGE_SEL — Take ana_bist_smplr_clkedge from dig logic
  [18] CLK0_TM_BIST_SMPLR_CLK_EDGE — set ana_bist_smplr_clkedge to posedge
  [17] CLK0_TM_BIST_EN_SEL — Take ana_bist_en from dig logic
  [16] CLK0_TM_BIST_EN — set ana_bist_en to 0
  [15] CLK0_TM_LPTX_TRST_SEL — Take ana_lptx_trst from dig logic
  [14] CLK0_TM_LPTX_TRST — set ana_lptx_trst to 0
  [13] CLK0_TM_LPTX_RST_SEL — Take ana_lptx_rst from dig logic
  [12] CLK0_TM_LPTX_RST — set ana_lptx_rst to 0
  [11] CLK0_TM_LPTX_DP_SEL — give output for LPTX DP from dig logic
  [10] CLK0_TM_LPTX_DP — send 0 to LP TX Dp
  [9] CLK0_TM_LPTX_DN_SEL — give output for LPTX DN from dig logic
  [8] CLK0_TM_LPTX_DN — send 0 to LP TX Dn
  [7] CLK0_TM_LDO_REF_EN_SEL — Take ana_ldo_ref_en from dig logic
  [6] CLK0_TM_LDO_REF_EN — set ana_ldo_ref_en to 0
  [5] CLK0_TM_HSTX_TRST_SEL — Take ana_hstx_trst from dig logic
  [4] CLK0_TM_HSTX_TRST — set ana_hstx_trst to 0
  [3] CLK0_TM_HSTX_RQST_SEL — Take ana_hstx_rqst from dig logic
  [2] CLK0_TM_HSTX_RQST — set ana_hstx_rqst to 0
  [1] CLK0_TM_GLOBAL_PD_SEL — Take ana_global_pd from dig logic
  [0] CLK0_TM_GLOBAL_PD — set ana_global_pd to 0 (powered up)
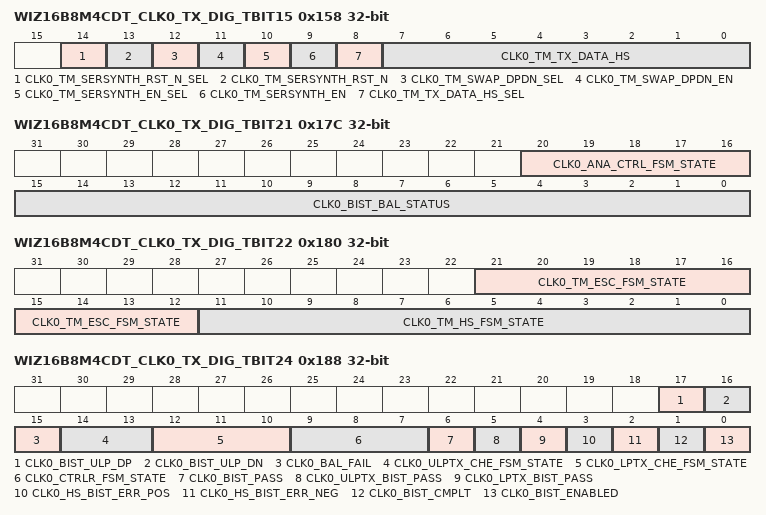
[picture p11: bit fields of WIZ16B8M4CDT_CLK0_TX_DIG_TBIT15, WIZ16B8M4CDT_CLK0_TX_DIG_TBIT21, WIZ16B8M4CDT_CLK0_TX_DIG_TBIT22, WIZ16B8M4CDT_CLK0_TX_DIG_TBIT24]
0x158 WIZ16B8M4CDT_CLK0_TX_DIG_TBIT15
  [14] CLK0_TM_SERSYNTH_RST_N_SEL — Take sersynth_rst_n from dig logic
  [13] CLK0_TM_SERSYNTH_RST_N — Set sersynth_rst_n to 1
  [12] CLK0_TM_SWAP_DPDN_SEL — Take swapdp_dn from dig logic
  [11] CLK0_TM_SWAP_DPDN_EN — Set swap_dpdn to 1
  [10] CLK0_TM_SERSYNTH_EN_SEL — Take sersynth_en from dig logic
  [9] CLK0_TM_SERSYNTH_EN — set sersynth_en to 1
  [8] CLK0_TM_TX_DATA_HS_SEL — sends single test byte to sersynth, which is in <7:0>
  [7:0] CLK0_TM_TX_DATA_HS — Test byte that can be sent constantly to sersynth. This is validated by bit <8> of this reg
{0x11C+4i} WIZ16B8M4CDT_CLK0_TX_DIG_TBIT{i} access not given reset not defined (i=16..20)
0x170 WIZ16B8M4CDT_CLK0_TX_ANA_TBIT5 ro
  [31:0] CLK0_ANA_TBIT5 — Analog Test register 5
0x17C WIZ16B8M4CDT_CLK0_TX_DIG_TBIT21 ro
  [20:16] CLK0_ANA_CTRL_FSM_STATE — FSM state readout for ana_ctrl
  [15:0] CLK0_BIST_BAL_STATUS — BAL logic status read
0x180 WIZ16B8M4CDT_CLK0_TX_DIG_TBIT22 ro
  [21:12] CLK0_TM_ESC_FSM_STATE — FSM state readout for escape path
  [11:0] CLK0_TM_HS_FSM_STATE — FSM state readout for hs path
0x188 WIZ16B8M4CDT_CLK0_TX_DIG_TBIT24 ro
  [17] CLK0_BIST_ULP_DP — Status of BIST ULPRX DP
  [16] CLK0_BIST_ULP_DN — Status of BIST ULPRX DN
  [15] CLK0_BAL_FAIL — byte alignment logic failed to give valid signal
  [14:13] CLK0_ULPTX_CHE_FSM_STATE — FSM state in which ULPTX checker is in
  [12:10] CLK0_LPTX_CHE_FSM_STATE — FSM state in which LPTX checker is in
  [9:7] CLK0_CTRLR_FSM_STATE — FSM state in which controller iscurrently
  [6] CLK0_BIST_PASS — Clock lane has passed BIST completely
  [5] CLK0_ULPTX_BIST_PASS — ULPTX Bist passed
  [4] CLK0_LPTX_BIST_PASS — LPTX Bist passed
  [3] CLK0_HS_BIST_ERR_POS — HS Bist error detected with posedge of sampler clock
  [2] CLK0_HS_BIST_ERR_NEG — HS Bist error detected with negedge of sampler clock
  [1] CLK0_BIST_CMPLT — BIST is completed
  [0] CLK0_BIST_ENABLED — BIST controller is enabled
{0x128+4i} WIZ16B8M4CDT_CLK0_TX_DIG_TBIT{i} access not given reset not defined (i=25..29)
{0x200+4i} WIZ16B8M4CDT_DL0_TX_ANA_TBIT{i} (i=0..4)
  [31:0] DL0_ANA_TBIT{i} — Analog Test register {i}
